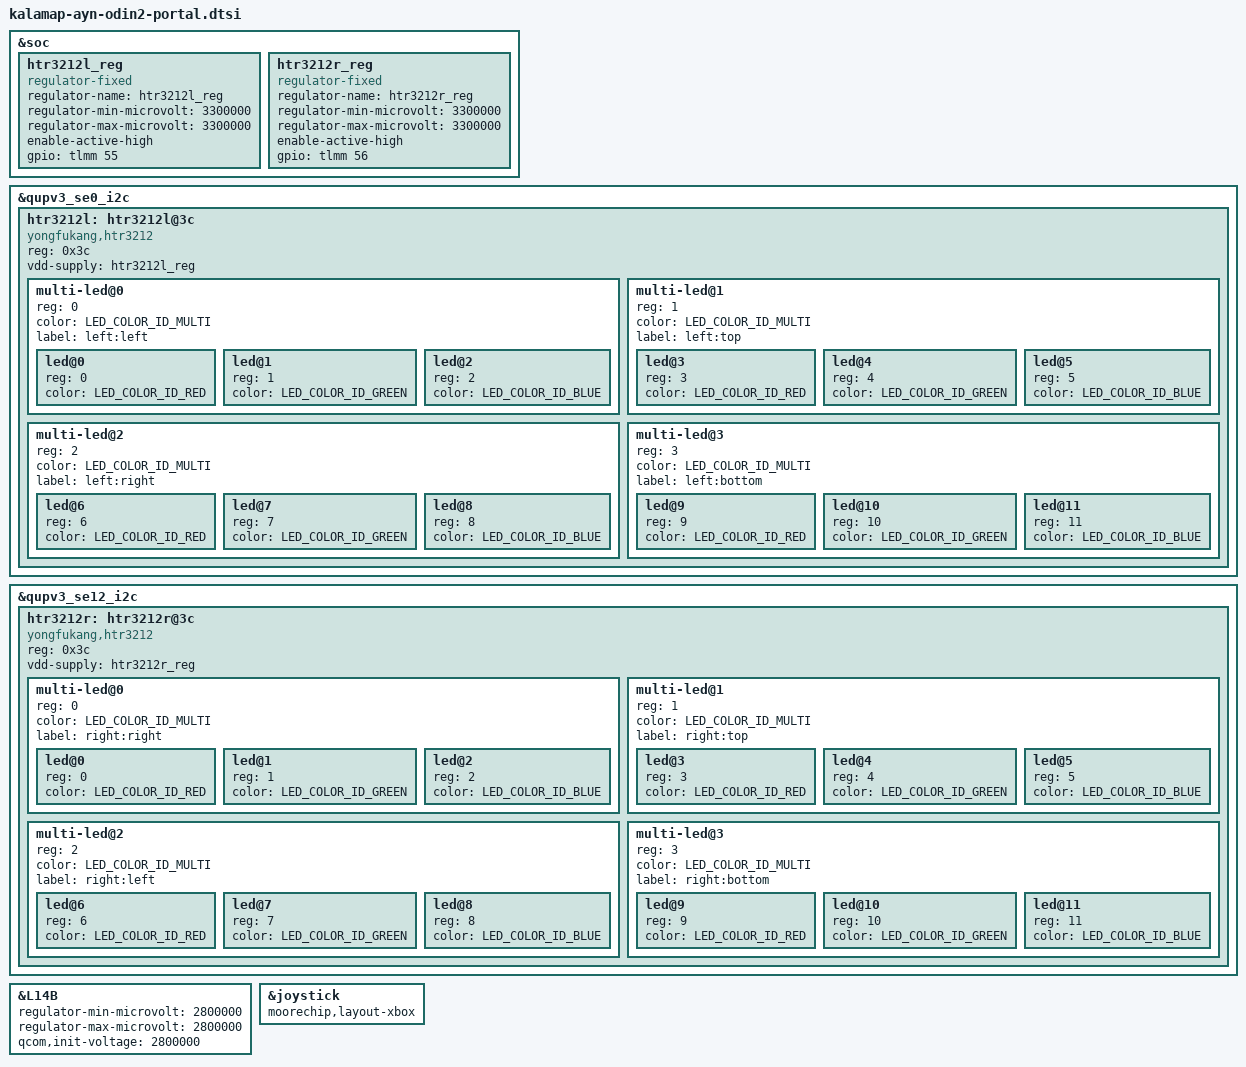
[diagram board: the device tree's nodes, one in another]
#include "kalamap-moorechip-common.dtsi"
#include <dt-bindings/leds/common.h>

&soc {
	htr3212l_reg: htr3212l_reg {
		compatible = "regulator-fixed";
		regulator-name = "htr3212l_reg";
		regulator-min-microvolt = <3300000>;
		regulator-max-microvolt = <3300000>;
		enable-active-high;
		gpio = <&tlmm 55 GPIO_ACTIVE_HIGH>;
	};
};

&qupv3_se0_i2c {
	#address-cells = <1>;
	#size-cells = <0>;
	status = "ok";

	htr3212l: htr3212l@3c {
		compatible = "yongfukang,htr3212";
		reg = <0x3c>;
		vdd-supply = <&htr3212l_reg>;

		multi-led@0 {
			#address-cells = <1>;
			#size-cells = <0>;
			reg = <0>;
			color = <LED_COLOR_ID_MULTI>;
			label = "left:left";

			led@0 {
				reg = <0>;
				color = <LED_COLOR_ID_RED>;
			};

			led@1 {
				reg = <1>;
				color = <LED_COLOR_ID_GREEN>;
			};

			led@2 {
				reg = <2>;
				color = <LED_COLOR_ID_BLUE>;
			};
		};

		multi-led@1 {
			#address-cells = <1>;
			#size-cells = <0>;
			reg = <1>;
			color = <LED_COLOR_ID_MULTI>;
			label = "left:top";

			led@3 {
				reg = <3>;
				color = <LED_COLOR_ID_RED>;
			};

			led@4 {
				reg = <4>;
				color = <LED_COLOR_ID_GREEN>;
			};

			led@5 {
				reg = <5>;
				color = <LED_COLOR_ID_BLUE>;
			};
		};

		multi-led@2 {
			#address-cells = <1>;
			#size-cells = <0>;
			reg = <2>;
			color = <LED_COLOR_ID_MULTI>;
			label = "left:right";

			led@6 {
				reg = <6>;
				color = <LED_COLOR_ID_RED>;
			};

			led@7 {
				reg = <7>;
				color = <LED_COLOR_ID_GREEN>;
			};

			led@8 {
				reg = <8>;
				color = <LED_COLOR_ID_BLUE>;
			};
		};

		multi-led@3 {
			#address-cells = <1>;
			#size-cells = <0>;
			reg = <3>;
			color = <LED_COLOR_ID_MULTI>;
			label = "left:bottom";

			led@9 {
				reg = <9>;
				color = <LED_COLOR_ID_RED>;
			};

			led@10 {
				reg = <10>;
				color = <LED_COLOR_ID_GREEN>;
			};

			led@11 {
				reg = <11>;
				color = <LED_COLOR_ID_BLUE>;
			};
		};
	};
};

&soc {
	htr3212r_reg: htr3212r_reg {
		compatible = "regulator-fixed";
		regulator-name = "htr3212r_reg";
		regulator-min-microvolt = <3300000>;
		regulator-max-microvolt = <3300000>;
		enable-active-high;
		gpio = <&tlmm 56 GPIO_ACTIVE_HIGH>;
	};
};

&qupv3_se12_i2c {
	#address-cells = <1>;
	#size-cells = <0>;
	status = "ok";

	htr3212r: htr3212r@3c {
		compatible = "yongfukang,htr3212";
		reg = <0x3c>;
		vdd-supply = <&htr3212r_reg>;

		multi-led@0 {
			#address-cells = <1>;
			#size-cells = <0>;
			reg = <0>;
			color = <LED_COLOR_ID_MULTI>;
			label = "right:right";

			led@0 {
				reg = <0>;
				color = <LED_COLOR_ID_RED>;
			};

			led@1 {
				reg = <1>;
				color = <LED_COLOR_ID_GREEN>;
			};

			led@2 {
				reg = <2>;
				color = <LED_COLOR_ID_BLUE>;
			};
		};

		multi-led@1 {
			#address-cells = <1>;
			#size-cells = <0>;
			reg = <1>;
			color = <LED_COLOR_ID_MULTI>;
			label = "right:top";

			led@3 {
				reg = <3>;
				color = <LED_COLOR_ID_RED>;
			};

			led@4 {
				reg = <4>;
				color = <LED_COLOR_ID_GREEN>;
			};

			led@5 {
				reg = <5>;
				color = <LED_COLOR_ID_BLUE>;
			};
		};

		multi-led@2 {
			#address-cells = <1>;
			#size-cells = <0>;
			reg = <2>;
			color = <LED_COLOR_ID_MULTI>;
			label = "right:left";

			led@6 {
				reg = <6>;
				color = <LED_COLOR_ID_RED>;
			};

			led@7 {
				reg = <7>;
				color = <LED_COLOR_ID_GREEN>;
			};

			led@8 {
				reg = <8>;
				color = <LED_COLOR_ID_BLUE>;
			};
		};

		multi-led@3 {
			#address-cells = <1>;
			#size-cells = <0>;
			reg = <3>;
			color = <LED_COLOR_ID_MULTI>;
			label = "right:bottom";

			led@9 {
				reg = <9>;
				color = <LED_COLOR_ID_RED>;
			};

			led@10 {
				reg = <10>;
				color = <LED_COLOR_ID_GREEN>;
			};

			led@11 {
				reg = <11>;
				color = <LED_COLOR_ID_BLUE>;
			};
		};
	};
};

&L14B {
	regulator-min-microvolt = <2800000>;
	regulator-max-microvolt = <2800000>;
	qcom,init-voltage = <2800000>;
};

&joystick {
	moorechip,layout-xbox;
};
